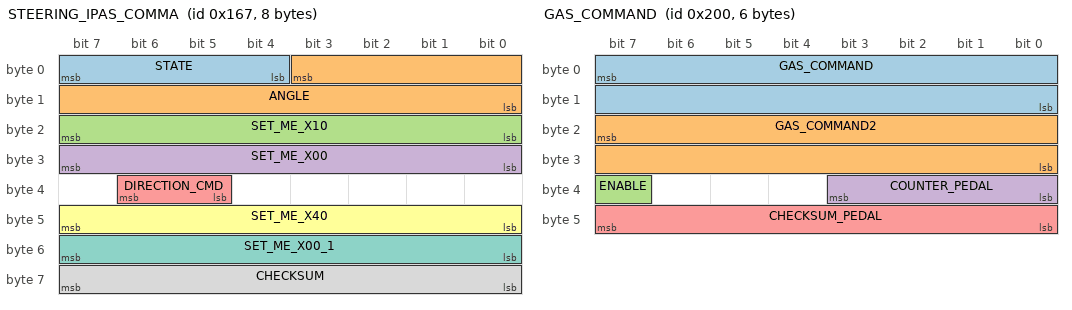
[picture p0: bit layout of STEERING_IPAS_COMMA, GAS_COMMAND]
BO_ 359 STEERING_IPAS_COMMA: 8 IPAS
 SG_ STATE : 7|4@0+ (1,0) [0|15] "" XXX
 SG_ ANGLE : 3|12@0- (1.5,0) [-510|510] "deg" XXX
 SG_ SET_ME_X10 : 23|8@0+ (1,0) [0|255] "" XXX
 SG_ SET_ME_X00 : 31|8@0+ (1,0) [0|255] "" XXX
 SG_ DIRECTION_CMD : 38|2@0+ (1,0) [0|3] "" XXX
 SG_ SET_ME_X40 : 47|8@0+ (1,0) [0|255] "" XXX
 SG_ SET_ME_X00_1 : 55|8@0+ (1,0) [0|255] "" XXX
 SG_ CHECKSUM : 63|8@0+ (1,0) [0|255] "" XXX

CM_ "BO_ STEERING_IPAS_COMMA: Copy of msg 614 so we can do angle control while the Park Assist ECU is connected (Panda spoofs 614 with 359 on connector J70). Note that addresses 0x266 and 0x167 are checksum-invariant";

BO_ 512 GAS_COMMAND: 6 EON
 SG_ GAS_COMMAND : 7|16@0+ (0.159375,-75.555) [0|1] "" INTERCEPTOR
 SG_ GAS_COMMAND2 : 23|16@0+ (0.159375,-151.111) [0|1] "" INTERCEPTOR
 SG_ ENABLE : 39|1@0+ (1,0) [0|1] "" INTERCEPTOR
 SG_ COUNTER_PEDAL : 35|4@0+ (1,0) [0|15] "" INTERCEPTOR
 SG_ CHECKSUM_PEDAL : 47|8@0+ (1,0) [0|255] "" INTERCEPTOR

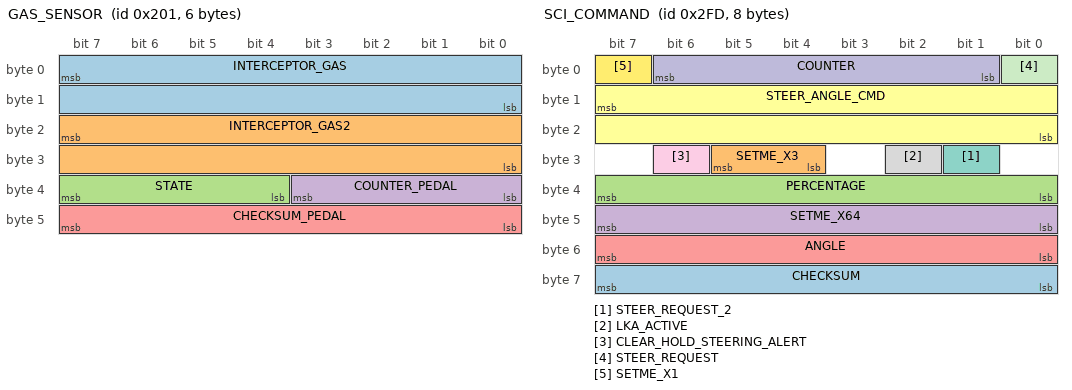
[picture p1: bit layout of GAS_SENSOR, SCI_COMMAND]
BO_ 513 GAS_SENSOR: 6 INTERCEPTOR
 SG_ INTERCEPTOR_GAS : 7|16@0+ (1,0) [0|1] "" EON
 SG_ INTERCEPTOR_GAS2 : 23|16@0+ (1,0) [0|1] "" EON
 SG_ STATE : 39|4@0+ (1,0) [0|15] "" EON
 SG_ COUNTER_PEDAL : 35|4@0+ (1,0) [0|15] "" EON
 SG_ CHECKSUM_PEDAL : 47|8@0+ (1,0) [0|255] "" EON

VAL_ 513 STATE 5 "FAULT_TIMEOUT" 4 "FAULT_STARTUP" 3 "FAULT_SCE" 2 "FAULT_SEND" 1 "FAULT_BAD_CHECKSUM" 0 "NO_FAULT" ;

BO_ 35 SECONDARY_STEER_ANGLE: 8 XXX
 SG_ ZORRO_STEER : 7|24@0- (0.004901594652,0) [-500|500] "" XXX

CM_ "BO_ SECONDARY_STEER_ANGLE: ZSS is a high-precision steering angle sensor that can replace the lower resolution sensor in most TSS1 Toyotas. Learn more: https://github.com/commaai/openpilot/wiki/Toyota-Lexus#zorro-steering-sensor-zss";

BO_ 767 SDSU: 8 XXX
 SG_ FD_BUTTON : 7|1@0+ (1,0) [0|1] "" XXX

CM_ "BO_ SDSU: The sDSU is a modified DSU for use in TSS1 Toyotas. Learn more: https://github.com/wocsor/panda/tree/smart_dsu";
CM_ SG_ 767 FD_BUTTON "The follow distance button signal as forwarded by the sdsu";

BO_ 766 SCI: 8 XXX
 SG_ FD_BUTTON : 7|1@0+ (1,0) [0|1] "" XXX

CM_ "BO_ SCI: Steering Control Interceptor/Injector";
CM_ SG_ 766 FD_BUTTON "Dummy";

BO_ 765 SCI_COMMAND: 8 XXX
 SG_ CHECKSUM : 63|8@0+ (1,0) [0|255] "" XXX
 SG_ SETME_X3 : 29|2@0+ (1,0) [0|3] "" XXX
 SG_ PERCENTAGE : 39|8@0+ (1,0) [0|255] "" XXX
 SG_ SETME_X64 : 47|8@0+ (1,0) [0|255] "" XXX
 SG_ ANGLE : 55|8@0- (0.5,0) [0|255] "" XXX
 SG_ STEER_ANGLE_CMD : 15|16@0- (0.0573,0) [-540|540] "" XXX
 SG_ STEER_REQUEST_2 : 25|1@0+ (1,0) [0|1] "" XXX
 SG_ LKA_ACTIVE : 26|1@0+ (1,0) [0|1] "" XXX
 SG_ CLEAR_HOLD_STEERING_ALERT : 30|1@0+ (1,0) [0|1] "" XXX
 SG_ COUNTER : 6|6@0+ (1,0) [0|255] "" XXX
 SG_ STEER_REQUEST : 0|1@0+ (1,0) [0|1] "" XXX
 SG_ SETME_X1 : 7|1@0+ (1,0) [0|1] "" XXX

CM_ "BO_ SCI_COMMAND: Command for SCI";
CM_ SG_ 765 PERCENTAGE "driver override percentage (0-100), very close to steeringPressed in OP";
CM_ SG_ 765 SETME_X64 "ramps to 0 smoothly then back on falling edge of STEER_REQUEST if BIT isn't 1";
CM_ SG_ 765 ANGLE "angle of car relative to lane center on LTA camera";
CM_ SG_ 765 STEER_ANGLE_CMD "desired angle, OEM steers up to 95 degrees, no angle limit but torque will bottom out";
CM_ SG_ 765 CLEAR_HOLD_STEERING_ALERT "set to 1 when user clears LKAS_HUD->LDA_ALERT ('Hold Steering') by applying torque to steering wheel";
CM_ SG_ 765 STEER_REQUEST "enable bit for steering, 1 to steer, 0 to not";
CM_ SG_ 765 STEER_REQUEST_2 "enable bit for steering, 1 to steer, 0 to not";
CM_ SG_ 765 LKA_ACTIVE "1 when using LTA for LKA";
CM_ SG_ 765 SETME_X1 "usually 1, seen at 0 on some South American Corollas indicating lack of stock Lane Tracing Assist";
CM_ SG_ 765 SETME_X3 "almost completely correlates with Toyota Safety Sense version, but may instead describe max torque when using LTA. if TSS 2.5 or 2022 RAV4, this is always 1. if TSS 2.0 this is always 3 (or 0 on Alphard, Highlander, NX)";
